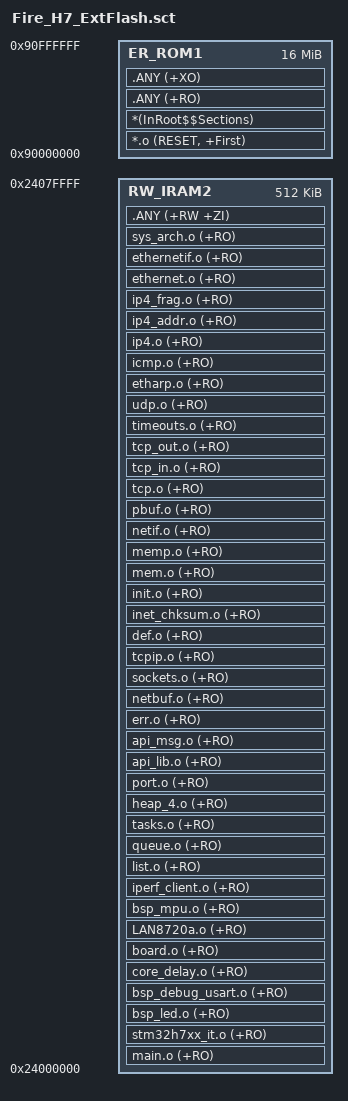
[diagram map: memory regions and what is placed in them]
; *************************************************************
; *** Scatter-Loading Description File generated by uVision ***
; *************************************************************

LR_ROM1 0x90000000 0x01000000  {    ; load region size_region
  ER_ROM1 0x90000000 0x01000000  {  ; load address = execution address
   *.o (RESET, +First)
   *(InRoot$$Sections)
   .ANY (+RO)
   .ANY (+XO)
  }
  RW_IRAM2 0x24000000 0x00080000  {  ; RW data
    main.o (+RO)
    stm32h7xx_it.o (+RO)
    bsp_led.o (+RO)
    bsp_debug_usart.o (+RO)
    core_delay.o (+RO)
;    bsp_key.o (+RO)
    board.o (+RO)
    LAN8720a.o (+RO)
    bsp_mpu.o (+RO)
    iperf_client.o (+RO)
;    croutine.o (+RO)
;    event_groups.o (+RO)
    list.o (+RO)
    queue.o (+RO)
    tasks.o (+RO)
;    timers.o (+RO)
    heap_4.o (+RO)
    port.o (+RO)
    api_lib.o (+RO)
    api_msg.o (+RO)
    err.o (+RO)
;    if_api.o (+RO)
    netbuf.o (+RO)
;    netdb.o (+RO)
;    netifapi.o (+RO)
    sockets.o (+RO)
    tcpip.o (+RO)
;    altcp.o (+RO)
;    altcp_alloc.o (+RO)
;    altcp_tcp.o (+RO)
    def.o (+RO)
;    dns.o (+RO)
    inet_chksum.o (+RO)
    init.o (+RO)
;    ip.o (+RO)
    mem.o (+RO)
    memp.o (+RO)
    netif.o (+RO)
    pbuf.o (+RO)
;    raw.o (+RO)
;    stats.o (+RO)
;    sys.o (+RO)
    tcp.o (+RO)
    tcp_in.o (+RO)
    tcp_out.o (+RO)
    timeouts.o (+RO)
    udp.o (+RO)
;    autoip.o (+RO)
;    dhcp.o (+RO)
    etharp.o (+RO)
    icmp.o (+RO)
;    igmp.o (+RO)
    ip4.o (+RO)
    ip4_addr.o (+RO)
    ip4_frag.o (+RO)
    ethernet.o (+RO)
    ethernetif.o (+RO)
    sys_arch.o (+RO)
   .ANY (+RW +ZI)
  }
}

